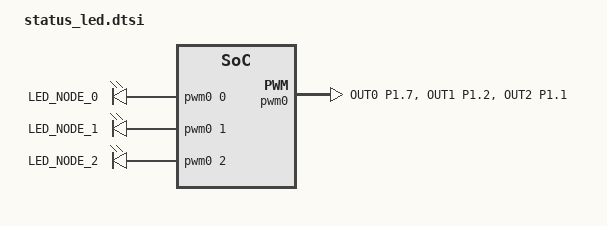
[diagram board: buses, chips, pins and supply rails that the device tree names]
#include <dt-bindings/led/led.h>

/ {
    chosen {
        zmk,backlight = &backlight;
    };

    backlight: pwmleds {
        compatible = "pwm-leds";
        pwm_led_0: led_0 {
            pwms = <&pwm0 0 PWM_MSEC(10) PWM_POLARITY_NORMAL>;
            label = "LED_NODE_0";
        };
        pwm_led_1: led_1 {
            pwms = <&pwm0 1 PWM_MSEC(10) PWM_POLARITY_NORMAL>;
            label = "LED_NODE_1";
        };
        pwm_led_2: led_2 {
            label = "LED_NODE_2";
            pwms = <&pwm0 2 PWM_MSEC(10) PWM_POLARITY_NORMAL>;
        };
    };
};


&pinctrl {
    pwm0_default: pwm0_default {
        group1 {
            psels = <NRF_PSEL(PWM_OUT0, 1, 7)>, // LED 0
                    <NRF_PSEL(PWM_OUT1, 1, 2)>, // LED 1
                    <NRF_PSEL(PWM_OUT2, 1, 1)>;  // LED 2
        };
    };
    pwm0_sleep: pwm0_sleep {
        group1 {
            psels = <NRF_PSEL(PWM_OUT0, 1, 7)>, // LED 0
                    <NRF_PSEL(PWM_OUT1, 1, 2)>, // LED 1
                    <NRF_PSEL(PWM_OUT2, 1, 1)>;  // LED 2
            low-power-enable;
        };
    };
};


&pwm0 {
    status = "okay";
    pinctrl-0 = <&pwm0_default>;
    pinctrl-1 = <&pwm0_sleep>;
    pinctrl-names = "default", "sleep";
};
